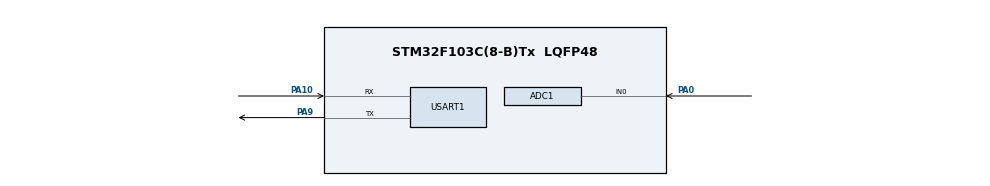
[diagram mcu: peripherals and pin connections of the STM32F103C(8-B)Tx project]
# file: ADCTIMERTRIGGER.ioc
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ADC1.Channel-0\#ChannelRegularConversion=ADC_CHANNEL_0
ADC1.ExternalTrigConv=ADC_EXTERNALTRIGCONV_T3_TRGO
ADC1.NbrOfConversion=1
ADC1.NbrOfConversionFlag=1
ADC1.Rank-0\#ChannelRegularConversion=1
ADC1.SamplingTime-0\#ChannelRegularConversion=ADC_SAMPLETIME_7CYCLES_5
ADC1.master=1
Mcu.Family=STM32F1
Mcu.Name=STM32F103C(8-B)Tx
Mcu.Package=LQFP48
NVIC.PriorityGroup=NVIC_PRIORITYGROUP_4
PA0-WKUP.Signal=ADCx_IN0
PA10.Mode=Asynchronous
PA10.Signal=USART1_RX
PA13.Mode=Serial_Wire
PA13.Signal=SYS_JTMS-SWDIO
PA14.Mode=Serial_Wire
PA14.Signal=SYS_JTCK-SWCLK
PA9.Mode=Asynchronous
PA9.Signal=USART1_TX
ProjectManager.HeapSize=0x200
ProjectManager.StackSize=0x400
ProjectManager.TargetToolchain=Makefile
RCC.APB1Freq_Value=8000000
RCC.APB2Freq_Value=8000000
SH.ADCx_IN0.0=ADC1_IN0,IN0
TIM3.Period=999
TIM3.Prescaler=7
TIM3.TIM_MasterOutputTrigger=TIM_TRGO_UPDATE
USART1.VirtualMode=VM_ASYNC
VP_TIM3_VS_ClockSourceINT.Mode=Internal
board=custom

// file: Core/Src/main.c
/* USER CODE BEGIN Header */
/**
  ******************************************************************************
  * @file           : main.c
  * @brief          : Main program body
  ******************************************************************************
  * @attention
  *
  * Copyright (c) 2026 STMicroelectronics.
  * All rights reserved.
  *
  * This software is licensed under terms that can be found in the LICENSE file
  * in the root directory of this software component.
  * If no LICENSE file comes with this software, it is provided AS-IS.
  *
  ******************************************************************************
  */
/* USER CODE END Header */
#include "main.h"
#include "string.h"
#include "stdio.h"

ADC_HandleTypeDef hadc1;

TIM_HandleTypeDef htim3;

UART_HandleTypeDef huart1;

void SystemClock_Config(void);
static void MX_GPIO_Init(void);
static void MX_ADC1_Init(void);
static void MX_TIM3_Init(void);
static void MX_USART1_UART_Init(void);

int main(void)
{

  /* MCU Configuration--------------------------------------------------------*/

  /* Reset of all peripherals, Initializes the Flash interface and the Systick. */
  HAL_Init();

  /* Configure the system clock */
  SystemClock_Config();

  /* Initialize all configured peripherals */
  MX_GPIO_Init();
  MX_ADC1_Init();
  MX_TIM3_Init();
  MX_USART1_UART_Init();
  /* USER CODE BEGIN 2 */
   HAL_TIM_Base_Start(&htim3);

   HAL_ADC_Start(&hadc1);

   /* ==== 临时诊断：初始化板载 LED (PC13) ==== */
   __HAL_RCC_GPIOC_CLK_ENABLE();
   GPIO_InitTypeDef led = {0};
   led.Pin   = GPIO_PIN_13;
   led.Mode  = GPIO_MODE_OUTPUT_PP;
   led.Speed = GPIO_SPEED_FREQ_LOW;
   HAL_GPIO_Init(GPIOC, &led);
   /* ==== 诊断代码结束 ==== */
  /* USER CODE END 2 */

  /* Infinite loop */
  /* USER CODE BEGIN WHILE */
  while (1)
  {
#if 1   /* ===== 诊断模式：绕过 ADC，只闪 LED + 发固定数据 ===== */
    HAL_GPIO_TogglePin(GPIOC, GPIO_PIN_13);
    HAL_UART_Transmit(&huart1, (uint8_t*)"D\r\n", 3, HAL_MAX_DELAY);
    HAL_Delay(300);

#else   /* ===== 正常模式：ADC 采样 ===== */
    HAL_ADC_PollForConversion(&hadc1, HAL_MAX_DELAY);// Wait for ADC conversion to complete

    uint32_t adcValue = HAL_ADC_GetValue(&hadc1); // Get the ADC value

    /* 换算成毫伏。用整数运算，避开浮点 printf —— newlib-nano 默认不链接
       _printf_float，%.3f 会打印成空白，VOFA+ 收到空行自然画不出波形 */
    uint32_t millivolt = (adcValue * 3300UL) / 4095UL;

    char buffer[32];// Create a buffer to hold the formatted string

    /* VOFA+ FireWater 协议：纯数字 + \n 结尾，多通道用逗号分隔 */
    sprintf(buffer, "%lu\n", millivolt);

    HAL_UART_Transmit(&huart1, (uint8_t*)buffer, strlen(buffer), HAL_MAX_DELAY);
#endif
    /* USER CODE END WHILE */

  }
}

void SystemClock_Config(void)
{
  RCC_OscInitTypeDef RCC_OscInitStruct = {0};
  RCC_ClkInitTypeDef RCC_ClkInitStruct = {0};
  RCC_PeriphCLKInitTypeDef PeriphClkInit = {0};

  /** Initializes the RCC Oscillators according to the specified parameters
  * in the RCC_OscInitTypeDef structure.
  */
  RCC_OscInitStruct.OscillatorType = RCC_OSCILLATORTYPE_HSI;
  RCC_OscInitStruct.HSIState = RCC_HSI_ON;
  RCC_OscInitStruct.HSICalibrationValue = RCC_HSICALIBRATION_DEFAULT;
  RCC_OscInitStruct.PLL.PLLState = RCC_PLL_NONE;
  if (HAL_RCC_OscConfig(&RCC_OscInitStruct) != HAL_OK)
  {
    Error_Handler();
  }

  /** Initializes the CPU, AHB and APB buses clocks
  */
  RCC_ClkInitStruct.ClockType = RCC_CLOCKTYPE_HCLK|RCC_CLOCKTYPE_SYSCLK
                              |RCC_CLOCKTYPE_PCLK1|RCC_CLOCKTYPE_PCLK2;
  RCC_ClkInitStruct.SYSCLKSource = RCC_SYSCLKSOURCE_HSI;
  RCC_ClkInitStruct.AHBCLKDivider = RCC_SYSCLK_DIV1;
  RCC_ClkInitStruct.APB1CLKDivider = RCC_HCLK_DIV1;
  RCC_ClkInitStruct.APB2CLKDivider = RCC_HCLK_DIV1;

  if (HAL_RCC_ClockConfig(&RCC_ClkInitStruct, FLASH_LATENCY_0) != HAL_OK)
  {
    Error_Handler();
  }
  PeriphClkInit.PeriphClockSelection = RCC_PERIPHCLK_ADC;
  PeriphClkInit.AdcClockSelection = RCC_ADCPCLK2_DIV2;
  if (HAL_RCCEx_PeriphCLKConfig(&PeriphClkInit) != HAL_OK)
  {
    Error_Handler();
  }
}

static void MX_ADC1_Init(void)
{

  ADC_ChannelConfTypeDef sConfig = {0};

  /** Common config
  */
  hadc1.Instance = ADC1;
  hadc1.Init.ScanConvMode = ADC_SCAN_DISABLE;
  hadc1.Init.ContinuousConvMode = DISABLE;
  hadc1.Init.DiscontinuousConvMode = DISABLE;
  hadc1.Init.ExternalTrigConv = ADC_EXTERNALTRIGCONV_T3_TRGO;
  hadc1.Init.DataAlign = ADC_DATAALIGN_RIGHT;
  hadc1.Init.NbrOfConversion = 1;
  if (HAL_ADC_Init(&hadc1) != HAL_OK)
  {
    Error_Handler();
  }

  /** Configure Regular Channel
  */
  sConfig.Channel = ADC_CHANNEL_0;
  sConfig.Rank = ADC_REGULAR_RANK_1;
  sConfig.SamplingTime = ADC_SAMPLETIME_7CYCLES_5;
  if (HAL_ADC_ConfigChannel(&hadc1, &sConfig) != HAL_OK)
  {
    Error_Handler();
  }

}

static void MX_TIM3_Init(void)
{

  TIM_ClockConfigTypeDef sClockSourceConfig = {0};
  TIM_MasterConfigTypeDef sMasterConfig = {0};

  htim3.Instance = TIM3;
  htim3.Init.Prescaler = 7;
  htim3.Init.CounterMode = TIM_COUNTERMODE_UP;
  htim3.Init.Period = 999;
  htim3.Init.ClockDivision = TIM_CLOCKDIVISION_DIV1;
  htim3.Init.AutoReloadPreload = TIM_AUTORELOAD_PRELOAD_DISABLE;
  if (HAL_TIM_Base_Init(&htim3) != HAL_OK)
  {
    Error_Handler();
  }
  sClockSourceConfig.ClockSource = TIM_CLOCKSOURCE_INTERNAL;
  if (HAL_TIM_ConfigClockSource(&htim3, &sClockSourceConfig) != HAL_OK)
  {
    Error_Handler();
  }
  sMasterConfig.MasterOutputTrigger = TIM_TRGO_UPDATE;
  sMasterConfig.MasterSlaveMode = TIM_MASTERSLAVEMODE_DISABLE;
  if (HAL_TIMEx_MasterConfigSynchronization(&htim3, &sMasterConfig) != HAL_OK)
  {
    Error_Handler();
  }

}

static void MX_USART1_UART_Init(void)
{

  huart1.Instance = USART1;
  huart1.Init.BaudRate = 115200;
  huart1.Init.WordLength = UART_WORDLENGTH_8B;
  huart1.Init.StopBits = UART_STOPBITS_1;
  huart1.Init.Parity = UART_PARITY_NONE;
  huart1.Init.Mode = UART_MODE_TX_RX;
  huart1.Init.HwFlowCtl = UART_HWCONTROL_NONE;
  huart1.Init.OverSampling = UART_OVERSAMPLING_16;
  if (HAL_UART_Init(&huart1) != HAL_OK)
  {
    Error_Handler();
  }

}

static void MX_GPIO_Init(void)
{

  /* GPIO Ports Clock Enable */
  __HAL_RCC_GPIOA_CLK_ENABLE();

}

void Error_Handler(void)
{
  __disable_irq();
  while (1)
  {
  }
}
